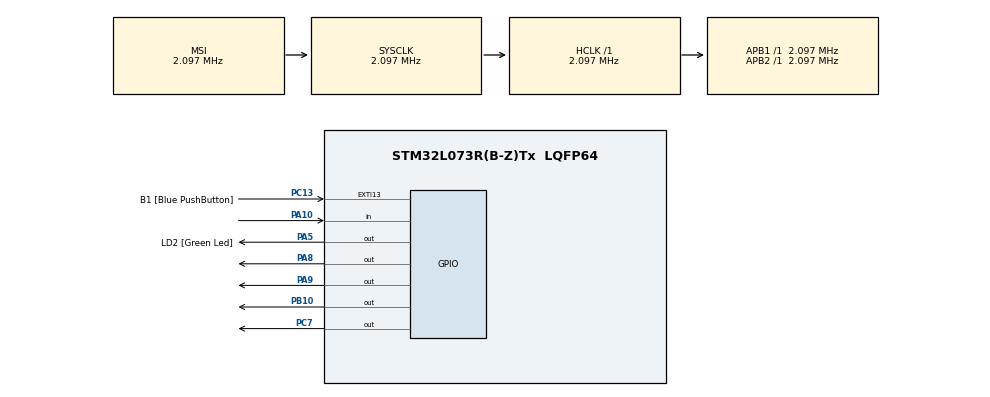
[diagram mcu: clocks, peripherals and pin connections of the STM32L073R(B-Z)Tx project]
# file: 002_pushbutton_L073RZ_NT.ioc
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Mcu.Family=STM32L0
Mcu.Name=STM32L073R(B-Z)Tx
Mcu.Package=LQFP64
PA10.Signal=GPIO_Input
PA2.GPIO_Label=USART_TX
PA2.Signal=USART2_TX
PA3.GPIO_Label=USART_RX
PA3.Signal=USART2_RX
PA5.GPIO_Label=LD2 [Green Led]
PA5.Signal=GPIO_Output
PA8.Signal=GPIO_Output
PA9.Signal=GPIO_Output
PB10.Signal=GPIO_Output
PC13.GPIO_Label=B1 [Blue PushButton]
PC13.GPIO_ModeDefaultEXTI=GPIO_MODE_IT_FALLING
PC13.Signal=GPXTI13
PC7.Signal=GPIO_Output
ProjectManager.HeapSize=0x200
ProjectManager.StackSize=0x400
ProjectManager.TargetToolchain=STM32CubeIDE
RCC.AHBFreq_Value=2097000
RCC.APB1Freq_Value=2097000
RCC.APB1TimFreq_Value=2097000
RCC.APB2Freq_Value=2097000
RCC.APB2TimFreq_Value=2097000
RCC.HSE_VALUE=8000000
RCC.HSI16_VALUE=16000000
RCC.HSI48_VALUE=48000000
RCC.HSI_VALUE=16000000
RCC.LSEState=RCC_LSE_ON
RCC.LSE_VALUE=32768
RCC.MSI_VALUE=2097000
RCC.SYSCLKFreq_VALUE=2097000
RCC.VCOOutputFreq_Value=48000000
board=NUCLEO-L073RZ

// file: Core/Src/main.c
/* USER CODE BEGIN Header */
/**
  ******************************************************************************
  * @file           : main.c
  * @brief          : Main program body
  ******************************************************************************
  * @attention
  *
  * <h2><center>&copy; Copyright (c) 2020 STMicroelectronics.
  * All rights reserved.</center></h2>
  *
  * This software component is licensed by ST under BSD 3-Clause license,
  * the "License"; You may not use this file except in compliance with the
  * License. You may obtain a copy of the License at:
  *                        opensource.org/licenses/BSD-3-Clause
  *
  ******************************************************************************
  */
/* USER CODE END Header */
#include "main.h"

void SystemClock_Config(void);
static void MX_GPIO_Init(void);

int main(void)
{

  /* MCU Configuration--------------------------------------------------------*/

  /* Reset of all peripherals, Initializes the Flash interface and the Systick. */
  HAL_Init();

  /* Configure the system clock */
  SystemClock_Config();

  /* Initialize all configured peripherals */
  MX_GPIO_Init();

  /* Infinite loop */
  /* USER CODE BEGIN WHILE */
  while (1)
  {
	  if(HAL_GPIO_ReadPin(GPIOA, GPIO_PIN_10) == 1)
	  {

	  HAL_GPIO_WritePin(GPIOA, GPIO_PIN_8, GPIO_PIN_SET);
	  HAL_GPIO_WritePin(GPIOA, GPIO_PIN_9, GPIO_PIN_SET);
	  HAL_GPIO_WritePin(GPIOB, GPIO_PIN_10, GPIO_PIN_SET);
	  HAL_GPIO_WritePin(GPIOC, GPIO_PIN_7, GPIO_PIN_SET);

	  }

	  else{

		  HAL_GPIO_WritePin(GPIOA, GPIO_PIN_8, GPIO_PIN_RESET);
		  HAL_GPIO_WritePin(GPIOA, GPIO_PIN_9, GPIO_PIN_RESET);
		  HAL_GPIO_WritePin(GPIOB, GPIO_PIN_10, GPIO_PIN_RESET);
		  HAL_GPIO_WritePin(GPIOC, GPIO_PIN_7, GPIO_PIN_RESET);
}

    /* USER CODE END WHILE */

  }
}

void SystemClock_Config(void)
{
  RCC_OscInitTypeDef RCC_OscInitStruct = {0};
  RCC_ClkInitTypeDef RCC_ClkInitStruct = {0};

  /** Configure the main internal regulator output voltage
  */
  __HAL_PWR_VOLTAGESCALING_CONFIG(PWR_REGULATOR_VOLTAGE_SCALE1);
  /** Initializes the RCC Oscillators according to the specified parameters
  * in the RCC_OscInitTypeDef structure.
  */
  RCC_OscInitStruct.OscillatorType = RCC_OSCILLATORTYPE_MSI;
  RCC_OscInitStruct.MSIState = RCC_MSI_ON;
  RCC_OscInitStruct.MSICalibrationValue = 0;
  RCC_OscInitStruct.MSIClockRange = RCC_MSIRANGE_5;
  RCC_OscInitStruct.PLL.PLLState = RCC_PLL_NONE;
  if (HAL_RCC_OscConfig(&RCC_OscInitStruct) != HAL_OK)
  {
    Error_Handler();
  }
  /** Initializes the CPU, AHB and APB buses clocks
  */
  RCC_ClkInitStruct.ClockType = RCC_CLOCKTYPE_HCLK|RCC_CLOCKTYPE_SYSCLK
                              |RCC_CLOCKTYPE_PCLK1|RCC_CLOCKTYPE_PCLK2;
  RCC_ClkInitStruct.SYSCLKSource = RCC_SYSCLKSOURCE_MSI;
  RCC_ClkInitStruct.AHBCLKDivider = RCC_SYSCLK_DIV1;
  RCC_ClkInitStruct.APB1CLKDivider = RCC_HCLK_DIV1;
  RCC_ClkInitStruct.APB2CLKDivider = RCC_HCLK_DIV1;

  if (HAL_RCC_ClockConfig(&RCC_ClkInitStruct, FLASH_LATENCY_0) != HAL_OK)
  {
    Error_Handler();
  }
}

static void MX_GPIO_Init(void)
{
  GPIO_InitTypeDef GPIO_InitStruct = {0};

  /* GPIO Ports Clock Enable */
  __HAL_RCC_GPIOC_CLK_ENABLE();
  __HAL_RCC_GPIOA_CLK_ENABLE();
  __HAL_RCC_GPIOB_CLK_ENABLE();

  /*Configure GPIO pin Output Level */
  HAL_GPIO_WritePin(GPIOA, LD2_Pin|GPIO_PIN_8|GPIO_PIN_9, GPIO_PIN_RESET);

  /*Configure GPIO pin Output Level */
  HAL_GPIO_WritePin(GPIOB, GPIO_PIN_10, GPIO_PIN_RESET);

  /*Configure GPIO pin Output Level */
  HAL_GPIO_WritePin(GPIOC, GPIO_PIN_7, GPIO_PIN_RESET);

  /*Configure GPIO pin : B1_Pin */
  GPIO_InitStruct.Pin = B1_Pin;
  GPIO_InitStruct.Mode = GPIO_MODE_IT_FALLING;
  GPIO_InitStruct.Pull = GPIO_NOPULL;
  HAL_GPIO_Init(B1_GPIO_Port, &GPIO_InitStruct);

  /*Configure GPIO pins : USART_TX_Pin USART_RX_Pin */
  GPIO_InitStruct.Pin = USART_TX_Pin|USART_RX_Pin;
  GPIO_InitStruct.Mode = GPIO_MODE_AF_PP;
  GPIO_InitStruct.Pull = GPIO_NOPULL;
  GPIO_InitStruct.Speed = GPIO_SPEED_FREQ_VERY_HIGH;
  GPIO_InitStruct.Alternate = GPIO_AF4_USART2;
  HAL_GPIO_Init(GPIOA, &GPIO_InitStruct);

  /*Configure GPIO pins : LD2_Pin PA8 PA9 */
  GPIO_InitStruct.Pin = LD2_Pin|GPIO_PIN_8|GPIO_PIN_9;
  GPIO_InitStruct.Mode = GPIO_MODE_OUTPUT_PP;
  GPIO_InitStruct.Pull = GPIO_NOPULL;
  GPIO_InitStruct.Speed = GPIO_SPEED_FREQ_LOW;
  HAL_GPIO_Init(GPIOA, &GPIO_InitStruct);

  /*Configure GPIO pin : PB10 */
  GPIO_InitStruct.Pin = GPIO_PIN_10;
  GPIO_InitStruct.Mode = GPIO_MODE_OUTPUT_PP;
  GPIO_InitStruct.Pull = GPIO_NOPULL;
  GPIO_InitStruct.Speed = GPIO_SPEED_FREQ_LOW;
  HAL_GPIO_Init(GPIOB, &GPIO_InitStruct);

  /*Configure GPIO pin : PC7 */
  GPIO_InitStruct.Pin = GPIO_PIN_7;
  GPIO_InitStruct.Mode = GPIO_MODE_OUTPUT_PP;
  GPIO_InitStruct.Pull = GPIO_NOPULL;
  GPIO_InitStruct.Speed = GPIO_SPEED_FREQ_LOW;
  HAL_GPIO_Init(GPIOC, &GPIO_InitStruct);

  /*Configure GPIO pin : PA10 */
  GPIO_InitStruct.Pin = GPIO_PIN_10;
  GPIO_InitStruct.Mode = GPIO_MODE_INPUT;
  GPIO_InitStruct.Pull = GPIO_PULLUP;
  HAL_GPIO_Init(GPIOA, &GPIO_InitStruct);

}

void Error_Handler(void)
{
}

/************************ (C) COPYRIGHT STMicroelectronics *****END OF FILE****/
